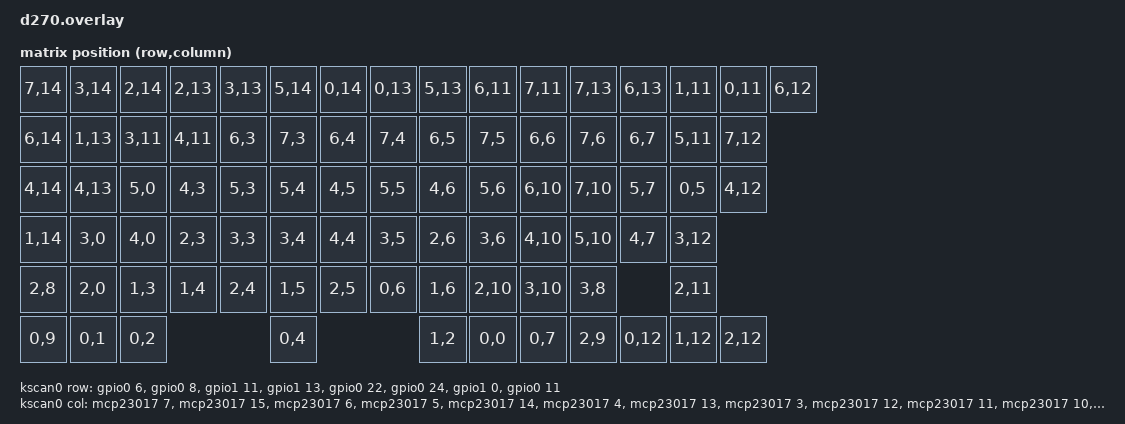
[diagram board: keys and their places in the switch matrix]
// This file was generated from a template. Edit it to match your keyboard.
// See https://zmk.dev/docs/development/hardware-integration/new-shield for more
// instructions.

#include <dt-bindings/zmk/matrix_transform.h>

#include "d270-layouts.dtsi"

/ {
    chosen {
        zmk,physical-layout = &default_layout;
    };

    kscan0: kscan0 {
        compatible = "zmk,kscan-matrix";
        wakeup-source;
        diode-direction = "col2row"; // Columns (MCP23017) are outputs, Rows (nRF) are inputs

        col-gpios
            = <&mcp23017 7  GPIO_ACTIVE_HIGH> /* Col Pin 4  */
            , <&mcp23017 15 GPIO_ACTIVE_HIGH> /* Col Pin 5  */
            , <&mcp23017 6  GPIO_ACTIVE_HIGH> /* Col Pin 6  */
            , <&mcp23017 5  GPIO_ACTIVE_HIGH> /* Col Pin 8  */
            , <&mcp23017 14 GPIO_ACTIVE_HIGH> /* Col Pin 9  */
            , <&mcp23017 4  GPIO_ACTIVE_HIGH> /* Col Pin 10 */
            , <&mcp23017 13 GPIO_ACTIVE_HIGH> /* Col Pin 11 */
            , <&mcp23017 3  GPIO_ACTIVE_HIGH> /* Col Pin 12 */
            , <&mcp23017 12 GPIO_ACTIVE_HIGH> /* Col Pin 13 */
            , <&mcp23017 11 GPIO_ACTIVE_HIGH> /* Col Pin 15 */
            , <&mcp23017 10 GPIO_ACTIVE_HIGH> /* Col Pin 19 */
            , <&mcp23017 9  GPIO_ACTIVE_HIGH> /* Col Pin 21 */
            , <&mcp23017 1  GPIO_ACTIVE_HIGH> /* Col Pin 22 */
            , <&mcp23017 2  GPIO_ACTIVE_HIGH> /* Col Pin 23 */
            , <&mcp23017 8  GPIO_ACTIVE_HIGH> /* Col Pin 24 */
            ;

        row-gpios
            = <&gpio0 6  (GPIO_ACTIVE_HIGH | GPIO_PULL_DOWN)> /* Row Pin 1  (D1) */
            , <&gpio0 8  (GPIO_ACTIVE_HIGH | GPIO_PULL_DOWN)> /* Row Pin 2  (D0) */
            , <&gpio1 11 (GPIO_ACTIVE_HIGH | GPIO_PULL_DOWN)> /* Row Pin 3  (D14) */
            , <&gpio1 13 (GPIO_ACTIVE_HIGH | GPIO_PULL_DOWN)> /* Row Pin 7  (D15) */
            , <&gpio0 22 (GPIO_ACTIVE_HIGH | GPIO_PULL_DOWN)> /* Row Pin 14 (D4) */
            , <&gpio0 24 (GPIO_ACTIVE_HIGH | GPIO_PULL_DOWN)> /* Row Pin 16 (D5) */
            , <&gpio1 0  (GPIO_ACTIVE_HIGH | GPIO_PULL_DOWN)> /* Row Pin 17 (D6) */
            , <&gpio0 11 (GPIO_ACTIVE_HIGH | GPIO_PULL_DOWN)> /* Row Pin 20 (D7) */
            ;
    };

    default_transform: default_transform {
        compatible = "zmk,matrix-transform";
        columns = <15>;
        rows = <8>;

        // Maps the electrical grid coordinates RC(Row, Col) 
        // directly to standard 1:1 physical key rows.
        map = <
            /* Row 0 (F-Row): 16 keys */
            RC(7,14) RC(3,14) RC(2,14) RC(2,13) RC(3,13) RC(5,14) RC(0,14) RC(0,13) RC(5,13) RC(6,11) RC(7,11) RC(7,13) RC(6,13) RC(1,11) RC(0,11) RC(6,12)
            /* Row 1 (Numbers): 15 keys */
            RC(6,14) RC(1,13) RC(3,11) RC(4,11) RC(6,3)  RC(7,3)  RC(6,4)  RC(7,4)  RC(6,5)  RC(7,5)  RC(6,6)  RC(7,6)  RC(6,7)  RC(5,11) RC(7,12)
            /* Row 2 (QWERTY): 15 keys */
            RC(4,14) RC(4,13) RC(5,0)  RC(4,3)  RC(5,3)  RC(5,4)  RC(4,5)  RC(5,5)  RC(4,6)  RC(5,6)  RC(6,10) RC(7,10) RC(5,7)  RC(0,5)  RC(4,12)
            /* Row 3 (ASDF): 14 keys */
            RC(1,14) RC(3,0)  RC(4,0)  RC(2,3)  RC(3,3)  RC(3,4)  RC(4,4)  RC(3,5)  RC(2,6)  RC(3,6)  RC(4,10) RC(5,10) RC(4,7)  RC(3,12)
            /* Row 4 (ZXCV): 13 keys */
            RC(2,8)  RC(2,0)  RC(1,3)  RC(1,4)  RC(2,4)  RC(1,5)  RC(2,5)  RC(0,6)  RC(1,6)  RC(2,10) RC(3,10) RC(3,8)           RC(2,11)
            /* Row 5 (Bottom Row): 11 keys */
            RC(0,9)  RC(0,1)  RC(0,2)                    RC(0,4)                    RC(1,2)  RC(0,0)  RC(0,7)  RC(2,9)  RC(0,12) RC(1,12) RC(2,12)
        >;
    };
};

&i2c0 {
    status = "okay";

    mcp23017: mcp23017@20 {
        compatible = "microchip,mcp230xx";
        reg = <0x20>; // Default address with A0, A1, A2 tied to GND
        gpio-controller;
        #gpio-cells = <2>;
        status = "okay";
		reg = <0x20>;
		ngpios = <16>;
        int-gpios = <&gpio0 2 (GPIO_ACTIVE_LOW | GPIO_PULL_UP)>;
    };
};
